VERSION ""

NS_ :

BS_:

BU_: IFC GW

BO_ 412 R_PBox1: 16 GW
 SG_ RTurnLmpSts_R_Pbox : 30|1@0+ (1,0) [0|1] " "  IFC
 SG_ LTurnLmpSts_R_Pbox : 31|1@0+ (1,0) [0|1] " "  IFC

BO_ 311 EPS_FD2: 64 GW
 SG_ VehSpd : 332|13@0+ (0.05625,0) [0|299.98125] "kph"  IFC
 SG_ VehSpdVld : 333|1@0+ (1,0) [0|1] " "  IFC

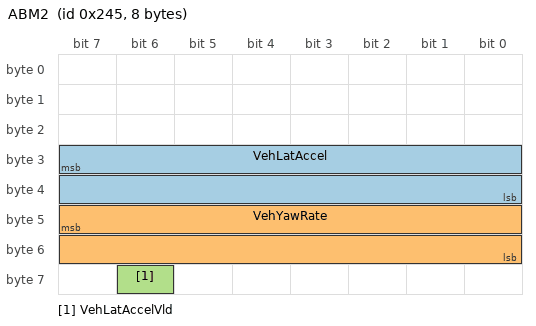
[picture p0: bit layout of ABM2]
BO_ 581 ABM2: 8 GW
 SG_ VehLatAccel : 31|16@0+ (0.00098,-21.592) [-21.592|21.592] "m/s^2"  IFC
 SG_ VehYawRate : 47|16@0+ (0.00024,-2.093) [-2.093|2.093] "rad/s"  IFC
 SG_ VehLatAccelVld : 62|1@0+ (1,0) [0|1] " "  IFC

BO_ 161 CSA2: 8 GW
 SG_ SteerWheelAng : 15|15@0+ (0.1,0) [0|780] "deg"  IFC
 SG_ SteerWheelAngSign : 16|1@0+ (1,0) [0|1] " "  IFC

BO_ 542 DCT_FD3: 64 GW
 SG_ CURRENT_GEAR : 119|4@0+ (1,0) [0|15] " "  IFC

BO_ 121 ECM_FD1: 64 GW
 SG_ BrkPedalSts : 275|2@0+ (1,0) [0|3] " "  IFC

BO_ 259 ECM_FD2: 64 GW
 SG_ AccelPedlPosnDiagc : 103|8@0+ (0.3937,0) [0|100.3935] "%"  IFC

BO_ 315 EPS_FD3: 64 GW
 SG_ FLWheelDriveDirection : 15|2@0+ (1,0) [0|3] " "  IFC
 SG_ FRWheelDriveDirection : 31|2@0+ (1,0) [0|3] " "  IFC
 SG_ RLWheelDriveDirection : 335|2@0+ (1,0) [0|3] " "  IFC
 SG_ RRWheelDriveDirection : 351|2@0+ (1,0) [0|3] " "  IFC

BA_DEF_ BO_  "CANFD_BRS" ENUM  "0","1";
BA_DEF_  "DBName" STRING ;
BA_DEF_  "BusType" STRING ;
BA_DEF_ BO_  "VFrameFormat" ENUM  "StandardCAN","ExtendedCAN","reserved","reserved","reserved","reserved","reserved","reserved","reserved","reserved","reserved","reserved","reserved","reserved","StandardCAN_FD","ExtendedCAN_FD";
BA_DEF_ BO_  "GenMsgILSupport" ENUM  "No","Yes";
BA_DEF_ BO_  "GenMsgCycleTime" INT 0 50000;
BA_DEF_ BO_  "GenMsgSendType" ENUM  "P","E","M","NotUsed","NotUsed","NotUsed","NotUsed","IfActive","NoMsgSendType","NotUsed","vector_leerstring";
BA_DEF_ SG_  "GenSigSendType" ENUM  "Cyclic","OnWrite","OnWriteWithRepetition","OnChange","OnChangeWithRepetition","IfActive","IfActiveWithRepetition","NoSigSendType","NotUsed","NotUsed","NotUsed","NotUsed","NotUsed";
BA_DEF_ SG_  "GenSigStartValue" FLOAT 0 100000000000;
BA_DEF_DEF_  "CANFD_BRS" "1";
BA_DEF_DEF_  "DBName" "";
BA_DEF_DEF_  "BusType" "";
BA_DEF_DEF_  "VFrameFormat" "StandardCAN";
BA_DEF_DEF_  "GenMsgILSupport" "Yes";
BA_DEF_DEF_  "GenMsgCycleTime" 0;
BA_DEF_DEF_  "GenMsgSendType" "P";
BA_DEF_DEF_  "GenSigSendType" "Cyclic";
BA_DEF_DEF_  "GenSigStartValue" 0;
BA_ "BusType" "CAN FD";
BA_ "DBName" "Fusion_Vehicle_CAN_DBC";
BA_ "GenMsgCycleTime" BO_ 412 50;
BA_ "VFrameFormat" BO_ 412 14;
BA_ "GenMsgCycleTime" BO_ 311 20;
BA_ "VFrameFormat" BO_ 311 14;
BA_ "GenMsgCycleTime" BO_ 581 20;
BA_ "VFrameFormat" BO_ 581 14;
BA_ "GenMsgCycleTime" BO_ 161 10;
BA_ "VFrameFormat" BO_ 161 14;
BA_ "GenMsgCycleTime" BO_ 542 20;
BA_ "VFrameFormat" BO_ 542 14;
BA_ "GenMsgCycleTime" BO_ 121 10;
BA_ "VFrameFormat" BO_ 121 14;
BA_ "GenMsgCycleTime" BO_ 259 20;
BA_ "VFrameFormat" BO_ 259 14;
BA_ "GenMsgCycleTime" BO_ 315 20;
BA_ "VFrameFormat" BO_ 315 14;
BA_ "GenSigStartValue" SG_ 581 VehLatAccel 22033;
BA_ "GenSigStartValue" SG_ 581 VehYawRate 8721;
VAL_ 412 RTurnLmpSts_R_Pbox 0 "Off" 1 "On" ;
VAL_ 412 LTurnLmpSts_R_Pbox 0 "Off" 1 "On" ;
VAL_ 311 VehSpdVld 0 "Invalid" 1 "Valid" ;
VAL_ 581 VehLatAccelVld 0 "Invalid" 1 "Valid" ;
VAL_ 161 SteerWheelAngSign 0 "Left (Positive)" 1 "Right (Negative)" ;
VAL_ 542 CURRENT_GEAR 0 "Current gear N or P" 1 "Current gear 1" 2 "Current gear 2" 3 "Current gear 3" 4 "Current gear 4" 5 "Current gear 5" 6 "Current gear 6" 7 "Current gear 7" 8 "Current gear R" 9 "Current gear 8" 10 "Current gear 9" ;
VAL_ 121 BrkPedalSts 0 "Not pressed" 1 "Pressed" 2 "Reserved" 3 "Error" ;
VAL_ 315 FLWheelDriveDirection 0 "Invalid" 1 "Forward" 2 "Backward" 3 "Stop" ;
VAL_ 315 FRWheelDriveDirection 0 "Invalid" 1 "Forward" 2 "Backward" 3 "Stop" ;
VAL_ 315 RLWheelDriveDirection 0 "Invalid" 1 "Forward" 2 "Backward" 3 "Stop" ;
VAL_ 315 RRWheelDriveDirection 0 "Invalid" 1 "Forward" 2 "Backward" 3 "Stop" ;
